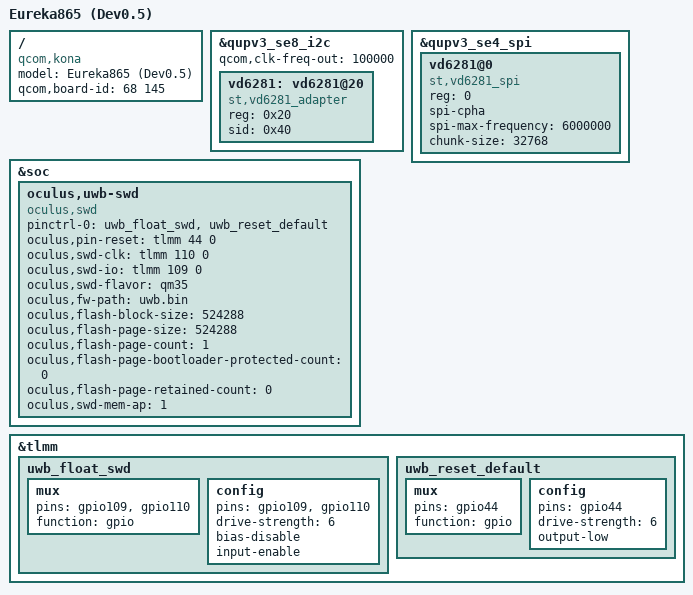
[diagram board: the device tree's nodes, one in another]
// SPDX-License-Identifier: GPL-2.0

/dts-v1/;
/plugin/;

#include "eureka865.dtsi"

/ {
	model = "Eureka865 (Dev0.5)";
	compatible = "qcom,kona";
	qcom,board-id = <68 145>;
};

&qupv3_se8_i2c {
	status = "ok";
	qcom,clk-freq-out = <100000>;

	vd6281: vd6281@20 {
		compatible = "st,vd6281_adapter";
		reg = <0x20>;
		sid = <0x40>;
		status = "ok";
	};
};

&qupv3_se4_spi {
	status = "ok";
	vd6281@0 {
		compatible = "st,vd6281_spi";
		reg = <0>;
		spi-cpha;
		spi-max-frequency = <6000000>;
		chunk-size = <32768>;
		status = "ok";
	};
};

&soc {
	oculus,uwb-swd {
		compatible = "oculus,swd";

		pinctrl-names = "default";
		pinctrl-0 = <&uwb_float_swd &uwb_reset_default>;

		oculus,pin-reset = <&tlmm 44 0>;
		oculus,swd-clk = <&tlmm 110 0>;
		oculus,swd-io = <&tlmm 109 0>;

		oculus,swd-flavor = "qm35";
		oculus,fw-path = "uwb.bin";
		/* 512 KiB of RRAM (not actual flash) */
		oculus,flash-block-size = <524288>;
		oculus,flash-page-size = <524288>;
		oculus,flash-page-count = <1>;
		oculus,flash-page-bootloader-protected-count = <0>;
		oculus,flash-page-retained-count = <0>;
		oculus,swd-mem-ap = <1>;
	};
};

&tlmm {
	uwb_float_swd: uwb_float_swd {
		mux {
			pins = "gpio109", "gpio110";
			function = "gpio";
		};

		config {
			pins = "gpio109", "gpio110";
			drive-strength = <6>;
			bias-disable;
			input-enable;
		};
	};

	uwb_reset_default: uwb_reset_default {
		mux {
			pins = "gpio44";
			function = "gpio";
		};

		config {
			pins = "gpio44";
			drive-strength = <6>;
			output-low;
		};
	};
};
